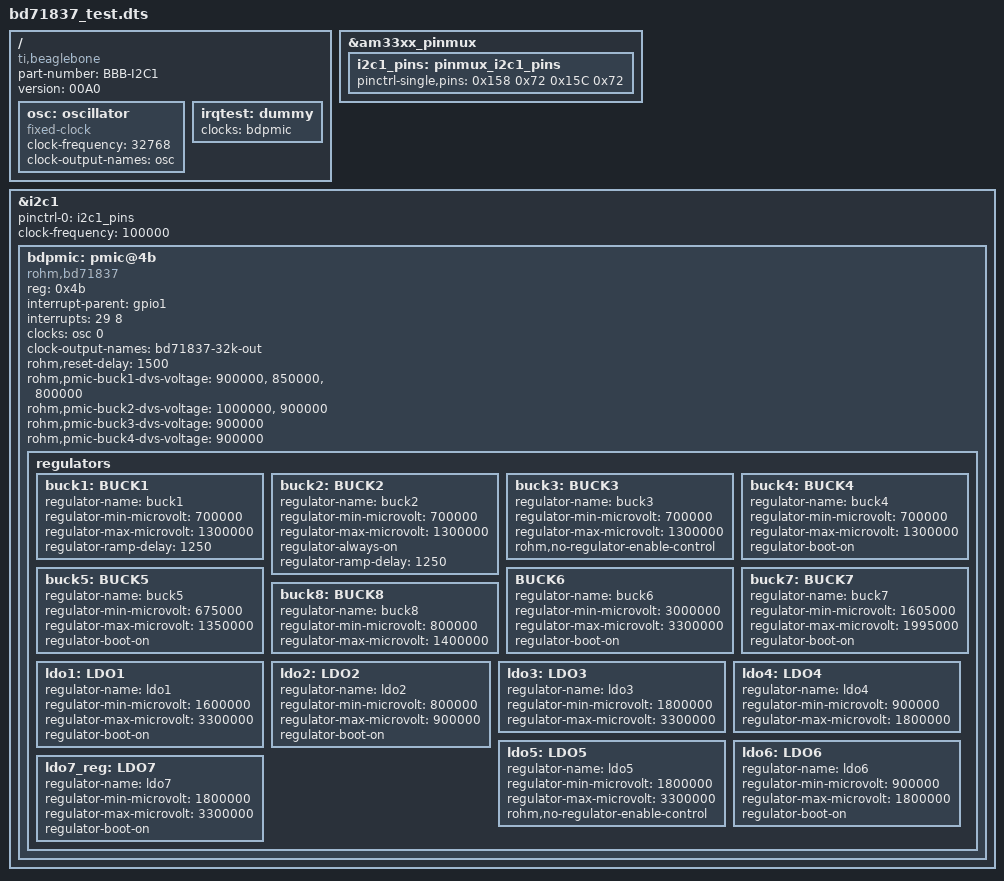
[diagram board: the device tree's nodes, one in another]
/dts-v1/;
/plugin/;

/{ /* this is our device tree overlay root node */

	compatible = "ti,beaglebone", "ti,beaglebone-black";
	part-number = "BBB-I2C1"; // you can choose any name here but it should be memorable
 	version = "00A0";

	fragment@0 {
		target = <&am33xx_pinmux>; // this is a link to an already defined node in the device tree, so that node is overlayed with our modification

		__overlay__ {
			i2c1_pins: pinmux_i2c1_pins {
				pinctrl-single,pins = <
          			0x158 0x72 /* spi0_d1.i2c1_sda */ 
          			0x15C 0x72 /* spi0_cs0.i2c1_sdl */
        			>;
			};
		};
	};
	fragment@1 {
		target-path = "/";
		__overlay__ {
			/* external oscillator */
			osc: oscillator {
				compatible = "fixed-clock";
				#clock-cells = <1>;
				clock-frequency  = <32768>;
				clock-output-names = "osc";
			};
		};
	};

	fragment@2 {
		target = <&i2c1>;

		__overlay__ {
			pinctrl-0 = <&i2c1_pins>;
			clock-frequency = <100000>;
			status = "okay";



			bdpmic: pmic@4b { /* the "test" defined as child of the i2c1 bus */
				compatible = "rohm,bd71837";
				reg = <0x4b>;
				/* GPIO 1_29 - (connector 8, pin 26) for irq */
				interrupt-parent = <&gpio1>;
/*				interrupts = <29 GPIO_ACTIVE_LOW>; */
				interrupts = <29 8>;
				clocks = <&osc 0>;
				#clock-cells = <0>;
				clock-output-names = "bd71837-32k-out";
				/* 1500 ms cold reset */
				rohm,reset-delay = <1500>;
				rohm,pmic-buck1-dvs-voltage = <900000>, <850000>, <800000>; /* VDD_SOC: Run-Idle-Suspend */
				rohm,pmic-buck2-dvs-voltage = <1000000>, <900000>; /* VDD_ARM: Run-Idle */
				rohm,pmic-buck3-dvs-voltage = <900000>; /* VDD_GPU Run */
				rohm,pmic-buck4-dvs-voltage = <900000>; /* VDD_VPU Run */

				regulators {
					buck1: BUCK1 {
						regulator-name = "buck1";
						regulator-min-microvolt = <700000>;
						regulator-max-microvolt = <1300000>;
/*						regulator-boot-on; */
/*						regulator-always-on; */
						regulator-ramp-delay = <1250>;
					};
					buck2: BUCK2 {
						regulator-name = "buck2";
						regulator-min-microvolt = <700000>;
						regulator-max-microvolt = <1300000>;
						regulator-always-on;
						regulator-ramp-delay = <1250>;
					};
					buck3: BUCK3 {
						regulator-name = "buck3";
						regulator-min-microvolt = <700000>;
						regulator-max-microvolt = <1300000>;
				//		regulator-boot-on;
						rohm,no-regulator-enable-control;
					};
					buck4: BUCK4 {
						regulator-name = "buck4";
						regulator-min-microvolt = <700000>;
						regulator-max-microvolt = <1300000>;
						regulator-boot-on;
					};
					buck5: BUCK5 {
						regulator-name = "buck5";
						regulator-min-microvolt = <675000>;
						regulator-max-microvolt = <1350000>;
						regulator-boot-on;
					};

					BUCK6: BUCK6 {
						regulator-name = "buck6";
						regulator-min-microvolt = <3000000>;
						regulator-max-microvolt = <3300000>;
						regulator-boot-on;
					};

					buck7: BUCK7 {
						regulator-name = "buck7";
						regulator-min-microvolt = <1605000>;
						regulator-max-microvolt = <1995000>;
						regulator-boot-on;
					};
		
					buck8: BUCK8 {
						regulator-name = "buck8";
						regulator-min-microvolt = <800000>;
						regulator-max-microvolt = <1400000>;
					};
			
/* LDO1 and LDO2 are enabled by HW when PMIC turns from READY to SNVS state */
					ldo1: LDO1 {
						regulator-name = "ldo1";
						regulator-min-microvolt = <1600000>;
						regulator-max-microvolt = <3300000>;
						regulator-boot-on;
/*						regulator-always-on; */
					};

					ldo2: LDO2 {
						regulator-name = "ldo2";
						regulator-min-microvolt = <800000>;
						regulator-max-microvolt = <900000>;
						regulator-boot-on;
/*						regulator-always-on; */
					};

					ldo3: LDO3 {
						regulator-name = "ldo3";
						regulator-min-microvolt = <1800000>;
						regulator-max-microvolt = <3300000>;
/*						regulator-boot-on; */
/*						regulator-always-on; */
					};

					ldo4: LDO4 {
						regulator-name = "ldo4";
						regulator-min-microvolt = <900000>;
						regulator-max-microvolt = <1800000>;
/*						regulator-boot-on; */
/*						regulator-always-on; */
					};

					ldo5: LDO5 {
						regulator-name = "ldo5";
						regulator-min-microvolt = <1800000>;
						regulator-max-microvolt = <3300000>;
						rohm,no-regulator-enable-control;
					};

					ldo6: LDO6 {
						regulator-name = "ldo6";
						regulator-min-microvolt = <900000>;
						regulator-max-microvolt = <1800000>;
						regulator-boot-on;
					};

					ldo7_reg: LDO7 {
						regulator-name = "ldo7";
						regulator-min-microvolt = <1800000>;
						regulator-max-microvolt = <3300000>;
						regulator-boot-on;
					};
				};
/*
				powerbtn: powerbtn {
					compatible = "rohm,bd71837-pwrkey";
					system-power-controller;
					interrupt-parent = <&bdpmic>;
					interrupts = <3>, <4>, <5>;
					interrupt-names = "pwr-btn", "pwr-btn-l", "pwr-btn-s";
					
				};
*/
			};
		};
	};

	fragment@3 {
		target-path = "/";
		__overlay__ {
			irqtest: dummy {
/*
				compatible = "rohm,foo-bd71837-irq";
				interrupt-parent = <&bdpmic>;
				interrupts = <0>, <1>, <2>, <3>, <4>, <5>, <6>;
				interrupt-names = "irq-btn", "irq-btn-s", "irq-btn-l", "irq-swrst", "irq-wdog", "irq-on", "irq-stb";
*/
				clocks = <&bdpmic>;
				clock-names = "foo-in";
			};
		};
	};
}; /* root node end */
